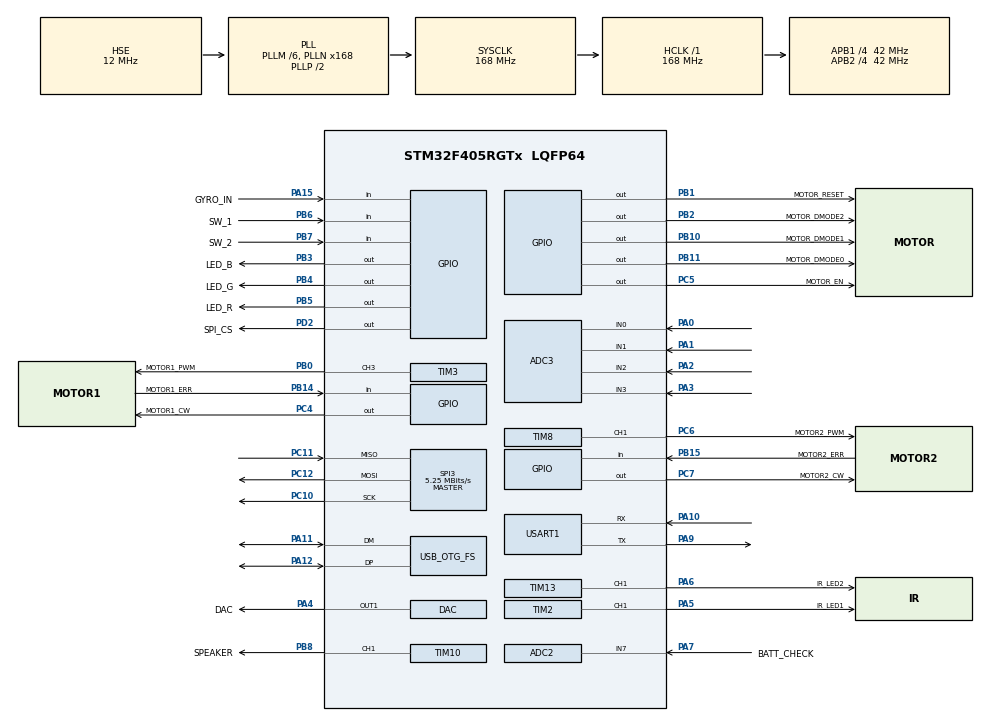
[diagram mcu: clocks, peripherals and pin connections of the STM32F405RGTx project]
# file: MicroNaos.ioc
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ADC2.Channel-0\#ChannelRegularConversion=ADC_CHANNEL_7
ADC2.ContinuousConvMode=DISABLE
ADC2.DMAContinuousRequests=DISABLE
ADC2.NbrOfConversionFlag=1
ADC2.Rank-0\#ChannelRegularConversion=1
ADC2.SamplingTime-0\#ChannelRegularConversion=ADC_SAMPLETIME_480CYCLES
ADC2.ScanConvMode=DISABLE
ADC3.Channel-0\#ChannelRegularConversion=ADC_CHANNEL_0
ADC3.Channel-1\#ChannelRegularConversion=ADC_CHANNEL_1
ADC3.Channel-2\#ChannelRegularConversion=ADC_CHANNEL_2
ADC3.Channel-3\#ChannelRegularConversion=ADC_CHANNEL_3
ADC3.ContinuousConvMode=ENABLE
ADC3.DMAContinuousRequests=ENABLE
ADC3.NbrOfConversion=4
ADC3.NbrOfConversionFlag=1
ADC3.Rank-0\#ChannelRegularConversion=1
ADC3.Rank-1\#ChannelRegularConversion=2
ADC3.Rank-2\#ChannelRegularConversion=3
ADC3.Rank-3\#ChannelRegularConversion=4
ADC3.SamplingTime-0\#ChannelRegularConversion=ADC_SAMPLETIME_28CYCLES
ADC3.SamplingTime-1\#ChannelRegularConversion=ADC_SAMPLETIME_28CYCLES
ADC3.SamplingTime-2\#ChannelRegularConversion=ADC_SAMPLETIME_28CYCLES
ADC3.SamplingTime-3\#ChannelRegularConversion=ADC_SAMPLETIME_28CYCLES
ADC3.ScanConvMode=ENABLE
Dma.ADC3.0.Direction=DMA_PERIPH_TO_MEMORY
Dma.ADC3.0.FIFOMode=DMA_FIFOMODE_DISABLE
Dma.ADC3.0.Instance=DMA2_Stream1
Dma.ADC3.0.MemDataAlignment=DMA_MDATAALIGN_HALFWORD
Dma.ADC3.0.MemInc=DMA_MINC_ENABLE
Dma.ADC3.0.Mode=DMA_CIRCULAR
Dma.ADC3.0.PeriphDataAlignment=DMA_PDATAALIGN_HALFWORD
Dma.ADC3.0.PeriphInc=DMA_PINC_DISABLE
Dma.ADC3.0.Priority=DMA_PRIORITY_VERY_HIGH
Dma.Request0=ADC3
Mcu.Family=STM32F4
Mcu.Name=STM32F405RGTx
Mcu.Package=LQFP64
NVIC.DMA2_Stream1_IRQn=true\:0\:0\:false\:false\:true\:false\:true\:true
NVIC.OTG_FS_IRQn=true\:0\:0\:false\:false\:true\:false\:true\:true
NVIC.PriorityGroup=NVIC_PRIORITYGROUP_4
NVIC.TIM1_TRG_COM_TIM11_IRQn=true\:0\:0\:false\:false\:true\:true\:true\:true
NVIC.TIM3_IRQn=true\:0\:0\:false\:false\:true\:true\:true\:true
NVIC.TIM6_DAC_IRQn=true\:0\:0\:false\:false\:true\:true\:true\:true
NVIC.TIM7_IRQn=true\:0\:0\:false\:false\:true\:true\:true\:true
NVIC.TIM8_UP_TIM13_IRQn=true\:0\:0\:false\:false\:true\:true\:true\:true
PA0-WKUP.Signal=ADCx_IN0
PA1.Signal=ADCx_IN1
PA10.Mode=Asynchronous
PA10.Signal=USART1_RX
PA11.Mode=Device_Only
PA11.Signal=USB_OTG_FS_DM
PA12.Mode=Device_Only
PA12.Signal=USB_OTG_FS_DP
PA13.Mode=Serial_Wire
PA13.Signal=SYS_JTMS-SWDIO
PA14.Mode=Serial_Wire
PA14.Signal=SYS_JTCK-SWCLK
PA15.GPIO_Label=GYRO_IN
PA15.Signal=GPIO_Input
PA2.Signal=ADCx_IN2
PA3.Signal=ADCx_IN3
PA4.GPIO_Label=DAC
PA4.Signal=COMP_DAC1_group
PA5.GPIO_Label=IR_LED1
PA5.Signal=S_TIM2_CH1_ETR
PA6.GPIO_Label=IR_LED2
PA6.Signal=S_TIM13_CH1
PA7.GPIO_Label=BATT_CHECK
PA7.Signal=ADCx_IN7
PA9.Mode=Asynchronous
PA9.Signal=USART1_TX
PB0.GPIO_Label=MOTOR1_PWM
PB0.Signal=S_TIM3_CH3
PB1.GPIO_Label=MOTOR_RESET
PB1.Signal=GPIO_Output
PB10.GPIO_Label=MOTOR_DMODE1
PB10.Signal=GPIO_Output
PB11.GPIO_Label=MOTOR_DMODE0
PB11.Signal=GPIO_Output
PB14.GPIO_Label=MOTOR1_ERR
PB14.Signal=GPIO_Input
PB15.GPIO_Label=MOTOR2_ERR
PB15.Signal=GPIO_Input
PB2.GPIO_Label=MOTOR_DMODE2
PB2.Signal=GPIO_Output
PB3.GPIO_Label=LED_B
PB3.Signal=GPIO_Output
PB4.GPIO_Label=LED_G
PB4.Signal=GPIO_Output
PB5.GPIO_Label=LED_R
PB5.Signal=GPIO_Output
PB6.GPIO_Label=SW_1
PB6.GPIO_PuPd=GPIO_PULLUP
PB6.Signal=GPIO_Input
PB7.GPIO_Label=SW_2
PB7.GPIO_PuPd=GPIO_PULLUP
PB7.Signal=GPIO_Input
PB8.GPIO_Label=SPEAKER
PB8.Signal=S_TIM10_CH1
PC10.Mode=Full_Duplex_Master
PC10.Signal=SPI3_SCK
PC11.Mode=Full_Duplex_Master
PC11.Signal=SPI3_MISO
PC12.Mode=Full_Duplex_Master
PC12.Signal=SPI3_MOSI
PC4.GPIO_Label=MOTOR1_CW
PC4.Signal=GPIO_Output
PC5.GPIO_Label=MOTOR_EN
PC5.Signal=GPIO_Output
PC6.GPIO_Label=MOTOR2_PWM
PC6.Signal=S_TIM8_CH1
PC7.GPIO_Label=MOTOR2_CW
PC7.Signal=GPIO_Output
PD2.GPIO_Label=SPI_CS
PD2.Signal=GPIO_Output
PH0-OSC_IN.Mode=HSE-External-Oscillator
PH0-OSC_IN.Signal=RCC_OSC_IN
PH1-OSC_OUT.Mode=HSE-External-Oscillator
PH1-OSC_OUT.Signal=RCC_OSC_OUT
ProjectManager.HeapSize=0x200
ProjectManager.StackSize=0x400
ProjectManager.TargetToolchain=Makefile
RCC.48MHZClocksFreq_Value=48000000
RCC.AHBFreq_Value=168000000
RCC.APB1CLKDivider=RCC_HCLK_DIV4
RCC.APB1Freq_Value=42000000
RCC.APB1TimFreq_Value=84000000
RCC.APB2CLKDivider=RCC_HCLK_DIV4
RCC.APB2Freq_Value=42000000
RCC.APB2TimFreq_Value=84000000
RCC.CortexFreq_Value=168000000
RCC.HCLKFreq_Value=168000000
RCC.HSE_VALUE=12000000
RCC.HSI_VALUE=16000000
RCC.LSE_VALUE=32768
RCC.PLLM=6
RCC.PLLN=168
RCC.PLLQ=7
RCC.SYSCLKFreq_VALUE=168000000
RCC.SYSCLKSource=RCC_SYSCLKSOURCE_PLLCLK
RCC.VCOOutputFreq_Value=336000000
SH.ADCx_IN0.0=ADC1_IN0
SH.ADCx_IN0.1=ADC3_IN0,IN0
SH.ADCx_IN1.0=ADC1_IN1
SH.ADCx_IN1.1=ADC3_IN1,IN1
SH.ADCx_IN2.0=ADC1_IN2
SH.ADCx_IN2.1=ADC3_IN2,IN2
SH.ADCx_IN3.0=ADC1_IN3
SH.ADCx_IN3.1=ADC3_IN3,IN3
SH.ADCx_IN7.0=ADC2_IN7,IN7
SH.COMP_DAC1_group.0=DAC_OUT1,DAC_OUT1
SH.S_TIM10_CH1.0=TIM10_CH1,PWM Generation1 CH1
SH.S_TIM13_CH1.0=TIM13_CH1,PWM Generation1 CH1
SH.S_TIM2_CH1_ETR.0=TIM2_CH1,PWM Generation1 CH1
SH.S_TIM3_CH3.0=TIM3_CH3,PWM Generation3 CH3
SH.S_TIM8_CH1.0=TIM8_CH1,PWM Generation1 CH1
SPI3.BaudRatePrescaler=SPI_BAUDRATEPRESCALER_8
SPI3.CLKPhase=SPI_PHASE_2EDGE
SPI3.CLKPolarity=SPI_POLARITY_HIGH
SPI3.CalculateBaudRate=5.25 MBits/s
SPI3.Direction=SPI_DIRECTION_2LINES
SPI3.Mode=SPI_MODE_MASTER
SPI3.VirtualType=VM_MASTER
TIM10.Channel=TIM_CHANNEL_1
TIM11.Period=10000 - 1
TIM11.Prescaler=84 - 1
TIM13.Channel=TIM_CHANNEL_1
TIM13.Period=100 - 1
TIM13.Prescaler=84 - 1
TIM2.Channel-PWM\ Generation1\ CH1=TIM_CHANNEL_1
TIM2.Period=100 - 1
TIM2.Prescaler=84 - 1
TIM3.AutoReloadPreload=TIM_AUTORELOAD_PRELOAD_ENABLE
TIM3.Channel-PWM\ Generation3\ CH3=TIM_CHANNEL_3
TIM3.Period=1000 - 1
TIM3.Prescaler=84 - 1
TIM6.Period=525 - 1
TIM6.Prescaler=0
TIM7.Period=1000 - 1
TIM7.Prescaler=84 - 1
TIM8.AutoReloadPreload=TIM_AUTORELOAD_PRELOAD_ENABLE
TIM8.Channel-PWM\ Generation1\ CH1=TIM_CHANNEL_1
TIM8.Period=1000 - 1
TIM8.Prescaler=84 - 1
USART1.VirtualMode=VM_ASYNC
USB_DEVICE.CLASS_NAME_FS=HID
USB_DEVICE.VirtualMode-HID_FS=Hid
USB_DEVICE.VirtualModeFS=Hid_FS
USB_OTG_FS.VirtualMode=Device_Only
VP_TIM10_VS_ClockSourceINT.Mode=Enable_Timer
VP_TIM11_VS_ClockSourceINT.Mode=Enable_Timer
VP_TIM13_VS_ClockSourceINT.Mode=Enable_Timer
VP_TIM6_VS_ClockSourceINT.Mode=Enable_Timer
VP_TIM7_VS_ClockSourceINT.Mode=Enable_Timer
VP_USB_DEVICE_VS_USB_DEVICE_HID_FS.Mode=HID_FS
board=custom

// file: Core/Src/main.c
/* USER CODE BEGIN Header */
/**
  ******************************************************************************
  * @file           : main.c
  * @brief          : Main program body
  ******************************************************************************
  * @attention
  *
  * <h2><center>&copy; Copyright (c) 2021 STMicroelectronics.
  * All rights reserved.</center></h2>
  *
  * This software component is licensed by ST under BSD 3-Clause license,
  * the "License"; You may not use this file except in compliance with the
  * License. You may obtain a copy of the License at:
  *                        opensource.org/licenses/BSD-3-Clause
  *
  ******************************************************************************
  */
/* USER CODE END Header */
#include "main.h"
#include "usb_device.h"

/* USER CODE BEGIN Includes */

#include "true_main.hpp"
#include "SEGGER_RTT.h"

/* USER CODE END Includes */

 ADC_HandleTypeDef hadc2;
ADC_HandleTypeDef hadc3;
DMA_HandleTypeDef hdma_adc3;

DAC_HandleTypeDef hdac;

SPI_HandleTypeDef hspi3;

TIM_HandleTypeDef htim2;
TIM_HandleTypeDef htim3;
TIM_HandleTypeDef htim6;
TIM_HandleTypeDef htim7;
TIM_HandleTypeDef htim8;
TIM_HandleTypeDef htim10;
TIM_HandleTypeDef htim11;
TIM_HandleTypeDef htim13;

UART_HandleTypeDef huart1;

void SystemClock_Config(void);
static void MX_GPIO_Init(void);
static void MX_DAC_Init(void);
static void MX_SPI3_Init(void);
static void MX_TIM2_Init(void);
static void MX_TIM10_Init(void);
static void MX_TIM13_Init(void);
static void MX_USART1_UART_Init(void);
static void MX_DMA_Init(void);
static void MX_TIM8_Init(void);
static void MX_TIM3_Init(void);
static void MX_ADC2_Init(void);
static void MX_TIM6_Init(void);
static void MX_TIM7_Init(void);
static void MX_ADC3_Init(void);
static void MX_TIM11_Init(void);

int main(void)
{

  /* MCU Configuration--------------------------------------------------------*/

  /* Reset of all peripherals, Initializes the Flash interface and the Systick. */
  HAL_Init();

  /* Configure the system clock */
  SystemClock_Config();

  /* Initialize all configured peripherals */
  MX_GPIO_Init();
  MX_DAC_Init();
  MX_SPI3_Init();
  MX_TIM2_Init();
  MX_TIM10_Init();
  MX_TIM13_Init();
  MX_USART1_UART_Init();
  MX_USB_DEVICE_Init();
  MX_DMA_Init();
  MX_TIM8_Init();
  MX_TIM3_Init();
  MX_ADC2_Init();
  MX_TIM6_Init();
  MX_TIM7_Init();
  MX_ADC3_Init();
  MX_TIM11_Init();

  /* Infinite loop */
  /* USER CODE BEGIN WHILE */
  while (1)
  {
	  true_main();
    /* USER CODE END WHILE */

  }
}

void SystemClock_Config(void)
{
  RCC_OscInitTypeDef RCC_OscInitStruct = {0};
  RCC_ClkInitTypeDef RCC_ClkInitStruct = {0};

  /** Configure the main internal regulator output voltage
  */
  __HAL_RCC_PWR_CLK_ENABLE();
  __HAL_PWR_VOLTAGESCALING_CONFIG(PWR_REGULATOR_VOLTAGE_SCALE1);

  /** Initializes the RCC Oscillators according to the specified parameters
  * in the RCC_OscInitTypeDef structure.
  */
  RCC_OscInitStruct.OscillatorType = RCC_OSCILLATORTYPE_HSE;
  RCC_OscInitStruct.HSEState = RCC_HSE_ON;
  RCC_OscInitStruct.PLL.PLLState = RCC_PLL_ON;
  RCC_OscInitStruct.PLL.PLLSource = RCC_PLLSOURCE_HSE;
  RCC_OscInitStruct.PLL.PLLM = 6;
  RCC_OscInitStruct.PLL.PLLN = 168;
  RCC_OscInitStruct.PLL.PLLP = RCC_PLLP_DIV2;
  RCC_OscInitStruct.PLL.PLLQ = 7;
  if (HAL_RCC_OscConfig(&RCC_OscInitStruct) != HAL_OK)
  {
    Error_Handler();
  }

  /** Initializes the CPU, AHB and APB buses clocks
  */
  RCC_ClkInitStruct.ClockType = RCC_CLOCKTYPE_HCLK|RCC_CLOCKTYPE_SYSCLK
                              |RCC_CLOCKTYPE_PCLK1|RCC_CLOCKTYPE_PCLK2;
  RCC_ClkInitStruct.SYSCLKSource = RCC_SYSCLKSOURCE_PLLCLK;
  RCC_ClkInitStruct.AHBCLKDivider = RCC_SYSCLK_DIV1;
  RCC_ClkInitStruct.APB1CLKDivider = RCC_HCLK_DIV4;
  RCC_ClkInitStruct.APB2CLKDivider = RCC_HCLK_DIV4;

  if (HAL_RCC_ClockConfig(&RCC_ClkInitStruct, FLASH_LATENCY_5) != HAL_OK)
  {
    Error_Handler();
  }
}

static void MX_ADC2_Init(void)
{

  ADC_ChannelConfTypeDef sConfig = {0};

  /** Configure the global features of the ADC (Clock, Resolution, Data Alignment and number of conversion)
  */
  hadc2.Instance = ADC2;
  hadc2.Init.ClockPrescaler = ADC_CLOCK_SYNC_PCLK_DIV2;
  hadc2.Init.Resolution = ADC_RESOLUTION_12B;
  hadc2.Init.ScanConvMode = DISABLE;
  hadc2.Init.ContinuousConvMode = DISABLE;
  hadc2.Init.DiscontinuousConvMode = DISABLE;
  hadc2.Init.ExternalTrigConvEdge = ADC_EXTERNALTRIGCONVEDGE_NONE;
  hadc2.Init.ExternalTrigConv = ADC_SOFTWARE_START;
  hadc2.Init.DataAlign = ADC_DATAALIGN_RIGHT;
  hadc2.Init.NbrOfConversion = 1;
  hadc2.Init.DMAContinuousRequests = DISABLE;
  hadc2.Init.EOCSelection = ADC_EOC_SINGLE_CONV;
  if (HAL_ADC_Init(&hadc2) != HAL_OK)
  {
    Error_Handler();
  }

  /** Configure for the selected ADC regular channel its corresponding rank in the sequencer and its sample time.
  */
  sConfig.Channel = ADC_CHANNEL_7;
  sConfig.Rank = 1;
  sConfig.SamplingTime = ADC_SAMPLETIME_480CYCLES;
  if (HAL_ADC_ConfigChannel(&hadc2, &sConfig) != HAL_OK)
  {
    Error_Handler();
  }

}

static void MX_ADC3_Init(void)
{

  ADC_ChannelConfTypeDef sConfig = {0};

  /** Configure the global features of the ADC (Clock, Resolution, Data Alignment and number of conversion)
  */
  hadc3.Instance = ADC3;
  hadc3.Init.ClockPrescaler = ADC_CLOCK_SYNC_PCLK_DIV2;
  hadc3.Init.Resolution = ADC_RESOLUTION_12B;
  hadc3.Init.ScanConvMode = ENABLE;
  hadc3.Init.ContinuousConvMode = ENABLE;
  hadc3.Init.DiscontinuousConvMode = DISABLE;
  hadc3.Init.ExternalTrigConvEdge = ADC_EXTERNALTRIGCONVEDGE_NONE;
  hadc3.Init.ExternalTrigConv = ADC_SOFTWARE_START;
  hadc3.Init.DataAlign = ADC_DATAALIGN_RIGHT;
  hadc3.Init.NbrOfConversion = 4;
  hadc3.Init.DMAContinuousRequests = ENABLE;
  hadc3.Init.EOCSelection = ADC_EOC_SINGLE_CONV;
  if (HAL_ADC_Init(&hadc3) != HAL_OK)
  {
    Error_Handler();
  }

  /** Configure for the selected ADC regular channel its corresponding rank in the sequencer and its sample time.
  */
  sConfig.Channel = ADC_CHANNEL_0;
  sConfig.Rank = 1;
  sConfig.SamplingTime = ADC_SAMPLETIME_28CYCLES;
  if (HAL_ADC_ConfigChannel(&hadc3, &sConfig) != HAL_OK)
  {
    Error_Handler();
  }

  /** Configure for the selected ADC regular channel its corresponding rank in the sequencer and its sample time.
  */
  sConfig.Channel = ADC_CHANNEL_1;
  sConfig.Rank = 2;
  if (HAL_ADC_ConfigChannel(&hadc3, &sConfig) != HAL_OK)
  {
    Error_Handler();
  }

  /** Configure for the selected ADC regular channel its corresponding rank in the sequencer and its sample time.
  */
  sConfig.Channel = ADC_CHANNEL_2;
  sConfig.Rank = 3;
  if (HAL_ADC_ConfigChannel(&hadc3, &sConfig) != HAL_OK)
  {
    Error_Handler();
  }

  /** Configure for the selected ADC regular channel its corresponding rank in the sequencer and its sample time.
  */
  sConfig.Channel = ADC_CHANNEL_3;
  sConfig.Rank = 4;
  if (HAL_ADC_ConfigChannel(&hadc3, &sConfig) != HAL_OK)
  {
    Error_Handler();
  }

}

static void MX_DAC_Init(void)
{

  DAC_ChannelConfTypeDef sConfig = {0};

  /** DAC Initialization
  */
  hdac.Instance = DAC;
  if (HAL_DAC_Init(&hdac) != HAL_OK)
  {
    Error_Handler();
  }

  /** DAC channel OUT1 config
  */
  sConfig.DAC_Trigger = DAC_TRIGGER_NONE;
  sConfig.DAC_OutputBuffer = DAC_OUTPUTBUFFER_ENABLE;
  if (HAL_DAC_ConfigChannel(&hdac, &sConfig, DAC_CHANNEL_1) != HAL_OK)
  {
    Error_Handler();
  }

}

static void MX_SPI3_Init(void)
{

  /* SPI3 parameter configuration*/
  hspi3.Instance = SPI3;
  hspi3.Init.Mode = SPI_MODE_MASTER;
  hspi3.Init.Direction = SPI_DIRECTION_2LINES;
  hspi3.Init.DataSize = SPI_DATASIZE_8BIT;
  hspi3.Init.CLKPolarity = SPI_POLARITY_HIGH;
  hspi3.Init.CLKPhase = SPI_PHASE_2EDGE;
  hspi3.Init.NSS = SPI_NSS_SOFT;
  hspi3.Init.BaudRatePrescaler = SPI_BAUDRATEPRESCALER_8;
  hspi3.Init.FirstBit = SPI_FIRSTBIT_MSB;
  hspi3.Init.TIMode = SPI_TIMODE_DISABLE;
  hspi3.Init.CRCCalculation = SPI_CRCCALCULATION_DISABLE;
  hspi3.Init.CRCPolynomial = 10;
  if (HAL_SPI_Init(&hspi3) != HAL_OK)
  {
    Error_Handler();
  }

}

static void MX_TIM2_Init(void)
{

  TIM_MasterConfigTypeDef sMasterConfig = {0};
  TIM_OC_InitTypeDef sConfigOC = {0};

  htim2.Instance = TIM2;
  htim2.Init.Prescaler = 84 - 1;
  htim2.Init.CounterMode = TIM_COUNTERMODE_UP;
  htim2.Init.Period = 100 - 1;
  htim2.Init.ClockDivision = TIM_CLOCKDIVISION_DIV1;
  htim2.Init.AutoReloadPreload = TIM_AUTORELOAD_PRELOAD_DISABLE;
  if (HAL_TIM_PWM_Init(&htim2) != HAL_OK)
  {
    Error_Handler();
  }
  sMasterConfig.MasterOutputTrigger = TIM_TRGO_RESET;
  sMasterConfig.MasterSlaveMode = TIM_MASTERSLAVEMODE_DISABLE;
  if (HAL_TIMEx_MasterConfigSynchronization(&htim2, &sMasterConfig) != HAL_OK)
  {
    Error_Handler();
  }
  sConfigOC.OCMode = TIM_OCMODE_PWM1;
  sConfigOC.Pulse = 0;
  sConfigOC.OCPolarity = TIM_OCPOLARITY_HIGH;
  sConfigOC.OCFastMode = TIM_OCFAST_DISABLE;
  if (HAL_TIM_PWM_ConfigChannel(&htim2, &sConfigOC, TIM_CHANNEL_1) != HAL_OK)
  {
    Error_Handler();
  }
  HAL_TIM_MspPostInit(&htim2);

}

static void MX_TIM3_Init(void)
{

  TIM_MasterConfigTypeDef sMasterConfig = {0};
  TIM_OC_InitTypeDef sConfigOC = {0};

  htim3.Instance = TIM3;
  htim3.Init.Prescaler = 84 - 1;
  htim3.Init.CounterMode = TIM_COUNTERMODE_UP;
  htim3.Init.Period = 1000 - 1;
  htim3.Init.ClockDivision = TIM_CLOCKDIVISION_DIV1;
  htim3.Init.AutoReloadPreload = TIM_AUTORELOAD_PRELOAD_ENABLE;
  if (HAL_TIM_PWM_Init(&htim3) != HAL_OK)
  {
    Error_Handler();
  }
  sMasterConfig.MasterOutputTrigger = TIM_TRGO_RESET;
  sMasterConfig.MasterSlaveMode = TIM_MASTERSLAVEMODE_DISABLE;
  if (HAL_TIMEx_MasterConfigSynchronization(&htim3, &sMasterConfig) != HAL_OK)
  {
    Error_Handler();
  }
  sConfigOC.OCMode = TIM_OCMODE_PWM1;
  sConfigOC.Pulse = 0;
  sConfigOC.OCPolarity = TIM_OCPOLARITY_HIGH;
  sConfigOC.OCFastMode = TIM_OCFAST_DISABLE;
  if (HAL_TIM_PWM_ConfigChannel(&htim3, &sConfigOC, TIM_CHANNEL_3) != HAL_OK)
  {
    Error_Handler();
  }
  HAL_TIM_MspPostInit(&htim3);

}

static void MX_TIM6_Init(void)
{

  TIM_MasterConfigTypeDef sMasterConfig = {0};

  htim6.Instance = TIM6;
  htim6.Init.Prescaler = 0;
  htim6.Init.CounterMode = TIM_COUNTERMODE_UP;
  htim6.Init.Period = 525 - 1;
  htim6.Init.AutoReloadPreload = TIM_AUTORELOAD_PRELOAD_DISABLE;
  if (HAL_TIM_Base_Init(&htim6) != HAL_OK)
  {
    Error_Handler();
  }
  sMasterConfig.MasterOutputTrigger = TIM_TRGO_RESET;
  sMasterConfig.MasterSlaveMode = TIM_MASTERSLAVEMODE_DISABLE;
  if (HAL_TIMEx_MasterConfigSynchronization(&htim6, &sMasterConfig) != HAL_OK)
  {
    Error_Handler();
  }

}

static void MX_TIM7_Init(void)
{

  TIM_MasterConfigTypeDef sMasterConfig = {0};

  htim7.Instance = TIM7;
  htim7.Init.Prescaler = 84 - 1;
  htim7.Init.CounterMode = TIM_COUNTERMODE_UP;
  htim7.Init.Period = 1000 - 1;
  htim7.Init.AutoReloadPreload = TIM_AUTORELOAD_PRELOAD_DISABLE;
  if (HAL_TIM_Base_Init(&htim7) != HAL_OK)
  {
    Error_Handler();
  }
  sMasterConfig.MasterOutputTrigger = TIM_TRGO_RESET;
  sMasterConfig.MasterSlaveMode = TIM_MASTERSLAVEMODE_DISABLE;
  if (HAL_TIMEx_MasterConfigSynchronization(&htim7, &sMasterConfig) != HAL_OK)
  {
    Error_Handler();
  }

}

static void MX_TIM8_Init(void)
{

  TIM_MasterConfigTypeDef sMasterConfig = {0};
  TIM_OC_InitTypeDef sConfigOC = {0};
  TIM_BreakDeadTimeConfigTypeDef sBreakDeadTimeConfig = {0};

  htim8.Instance = TIM8;
  htim8.Init.Prescaler = 84 - 1;
  htim8.Init.CounterMode = TIM_COUNTERMODE_UP;
  htim8.Init.Period = 1000 - 1;
  htim8.Init.ClockDivision = TIM_CLOCKDIVISION_DIV1;
  htim8.Init.RepetitionCounter = 0;
  htim8.Init.AutoReloadPreload = TIM_AUTORELOAD_PRELOAD_ENABLE;
  if (HAL_TIM_PWM_Init(&htim8) != HAL_OK)
  {
    Error_Handler();
  }
  sMasterConfig.MasterOutputTrigger = TIM_TRGO_RESET;
  sMasterConfig.MasterSlaveMode = TIM_MASTERSLAVEMODE_DISABLE;
  if (HAL_TIMEx_MasterConfigSynchronization(&htim8, &sMasterConfig) != HAL_OK)
  {
    Error_Handler();
  }
  sConfigOC.OCMode = TIM_OCMODE_PWM1;
  sConfigOC.Pulse = 0;
  sConfigOC.OCPolarity = TIM_OCPOLARITY_HIGH;
  sConfigOC.OCNPolarity = TIM_OCNPOLARITY_HIGH;
  sConfigOC.OCFastMode = TIM_OCFAST_DISABLE;
  sConfigOC.OCIdleState = TIM_OCIDLESTATE_RESET;
  sConfigOC.OCNIdleState = TIM_OCNIDLESTATE_RESET;
  if (HAL_TIM_PWM_ConfigChannel(&htim8, &sConfigOC, TIM_CHANNEL_1) != HAL_OK)
  {
    Error_Handler();
  }
  sBreakDeadTimeConfig.OffStateRunMode = TIM_OSSR_DISABLE;
  sBreakDeadTimeConfig.OffStateIDLEMode = TIM_OSSI_DISABLE;
  sBreakDeadTimeConfig.LockLevel = TIM_LOCKLEVEL_OFF;
  sBreakDeadTimeConfig.DeadTime = 0;
  sBreakDeadTimeConfig.BreakState = TIM_BREAK_DISABLE;
  sBreakDeadTimeConfig.BreakPolarity = TIM_BREAKPOLARITY_HIGH;
  sBreakDeadTimeConfig.AutomaticOutput = TIM_AUTOMATICOUTPUT_DISABLE;
  if (HAL_TIMEx_ConfigBreakDeadTime(&htim8, &sBreakDeadTimeConfig) != HAL_OK)
  {
    Error_Handler();
  }
  HAL_TIM_MspPostInit(&htim8);

}

static void MX_TIM10_Init(void)
{

  TIM_OC_InitTypeDef sConfigOC = {0};

  htim10.Instance = TIM10;
  htim10.Init.Prescaler = 0;
  htim10.Init.CounterMode = TIM_COUNTERMODE_UP;
  htim10.Init.Period = 65535;
  htim10.Init.ClockDivision = TIM_CLOCKDIVISION_DIV1;
  htim10.Init.AutoReloadPreload = TIM_AUTORELOAD_PRELOAD_DISABLE;
  if (HAL_TIM_Base_Init(&htim10) != HAL_OK)
  {
    Error_Handler();
  }
  if (HAL_TIM_PWM_Init(&htim10) != HAL_OK)
  {
    Error_Handler();
  }
  sConfigOC.OCMode = TIM_OCMODE_PWM1;
  sConfigOC.Pulse = 0;
  sConfigOC.OCPolarity = TIM_OCPOLARITY_HIGH;
  sConfigOC.OCFastMode = TIM_OCFAST_DISABLE;
  if (HAL_TIM_PWM_ConfigChannel(&htim10, &sConfigOC, TIM_CHANNEL_1) != HAL_OK)
  {
    Error_Handler();
  }
  HAL_TIM_MspPostInit(&htim10);

}

static void MX_TIM11_Init(void)
{

  htim11.Instance = TIM11;
  htim11.Init.Prescaler = 84 - 1;
  htim11.Init.CounterMode = TIM_COUNTERMODE_UP;
  htim11.Init.Period = 10000 - 1;
  htim11.Init.ClockDivision = TIM_CLOCKDIVISION_DIV1;
  htim11.Init.AutoReloadPreload = TIM_AUTORELOAD_PRELOAD_DISABLE;
  if (HAL_TIM_Base_Init(&htim11) != HAL_OK)
  {
    Error_Handler();
  }

}

static void MX_TIM13_Init(void)
{

  TIM_OC_InitTypeDef sConfigOC = {0};

  htim13.Instance = TIM13;
  htim13.Init.Prescaler = 84 - 1;
  htim13.Init.CounterMode = TIM_COUNTERMODE_UP;
  htim13.Init.Period = 100 - 1;
  htim13.Init.ClockDivision = TIM_CLOCKDIVISION_DIV1;
  htim13.Init.AutoReloadPreload = TIM_AUTORELOAD_PRELOAD_DISABLE;
  if (HAL_TIM_Base_Init(&htim13) != HAL_OK)
  {
    Error_Handler();
  }
  if (HAL_TIM_PWM_Init(&htim13) != HAL_OK)
  {
    Error_Handler();
  }
  sConfigOC.OCMode = TIM_OCMODE_PWM1;
  sConfigOC.Pulse = 0;
  sConfigOC.OCPolarity = TIM_OCPOLARITY_HIGH;
  sConfigOC.OCFastMode = TIM_OCFAST_DISABLE;
  if (HAL_TIM_PWM_ConfigChannel(&htim13, &sConfigOC, TIM_CHANNEL_1) != HAL_OK)
  {
    Error_Handler();
  }
  HAL_TIM_MspPostInit(&htim13);

}

static void MX_USART1_UART_Init(void)
{

  huart1.Instance = USART1;
  huart1.Init.BaudRate = 115200;
  huart1.Init.WordLength = UART_WORDLENGTH_8B;
  huart1.Init.StopBits = UART_STOPBITS_1;
  huart1.Init.Parity = UART_PARITY_NONE;
  huart1.Init.Mode = UART_MODE_TX_RX;
  huart1.Init.HwFlowCtl = UART_HWCONTROL_NONE;
  huart1.Init.OverSampling = UART_OVERSAMPLING_16;
  if (HAL_UART_Init(&huart1) != HAL_OK)
  {
    Error_Handler();
  }

}

static void MX_DMA_Init(void)
{

  /* DMA controller clock enable */
  __HAL_RCC_DMA2_CLK_ENABLE();

  /* DMA interrupt init */
  /* DMA2_Stream1_IRQn interrupt configuration */
  HAL_NVIC_SetPriority(DMA2_Stream1_IRQn, 0, 0);
  HAL_NVIC_EnableIRQ(DMA2_Stream1_IRQn);

}

static void MX_GPIO_Init(void)
{
  GPIO_InitTypeDef GPIO_InitStruct = {0};

  /* GPIO Ports Clock Enable */
  __HAL_RCC_GPIOH_CLK_ENABLE();
  __HAL_RCC_GPIOA_CLK_ENABLE();
  __HAL_RCC_GPIOC_CLK_ENABLE();
  __HAL_RCC_GPIOB_CLK_ENABLE();
  __HAL_RCC_GPIOD_CLK_ENABLE();

  /*Configure GPIO pin Output Level */
  HAL_GPIO_WritePin(GPIOC, MOTOR1_CW_Pin|MOTOR_EN_Pin|MOTOR2_CW_Pin, GPIO_PIN_RESET);

  /*Configure GPIO pin Output Level */
  HAL_GPIO_WritePin(GPIOB, MOTOR_RESET_Pin|MOTOR_DMODE2_Pin|MOTOR_DMODE1_Pin|MOTOR_DMODE0_Pin
                          |LED_B_Pin|LED_G_Pin|LED_R_Pin, GPIO_PIN_RESET);

  /*Configure GPIO pin Output Level */
  HAL_GPIO_WritePin(SPI_CS_GPIO_Port, SPI_CS_Pin, GPIO_PIN_RESET);

  /*Configure GPIO pins : PA0 PA1 PA2 PA3 */
  GPIO_InitStruct.Pin = GPIO_PIN_0|GPIO_PIN_1|GPIO_PIN_2|GPIO_PIN_3;
  GPIO_InitStruct.Mode = GPIO_MODE_ANALOG;
  GPIO_InitStruct.Pull = GPIO_NOPULL;
  HAL_GPIO_Init(GPIOA, &GPIO_InitStruct);

  /*Configure GPIO pins : MOTOR1_CW_Pin MOTOR_EN_Pin MOTOR2_CW_Pin */
  GPIO_InitStruct.Pin = MOTOR1_CW_Pin|MOTOR_EN_Pin|MOTOR2_CW_Pin;
  GPIO_InitStruct.Mode = GPIO_MODE_OUTPUT_PP;
  GPIO_InitStruct.Pull = GPIO_NOPULL;
  GPIO_InitStruct.Speed = GPIO_SPEED_FREQ_LOW;
  HAL_GPIO_Init(GPIOC, &GPIO_InitStruct);

  /*Configure GPIO pins : MOTOR_RESET_Pin MOTOR_DMODE2_Pin MOTOR_DMODE1_Pin MOTOR_DMODE0_Pin
                           LED_B_Pin LED_G_Pin LED_R_Pin */
  GPIO_InitStruct.Pin = MOTOR_RESET_Pin|MOTOR_DMODE2_Pin|MOTOR_DMODE1_Pin|MOTOR_DMODE0_Pin
                          |LED_B_Pin|LED_G_Pin|LED_R_Pin;
  GPIO_InitStruct.Mode = GPIO_MODE_OUTPUT_PP;
  GPIO_InitStruct.Pull = GPIO_NOPULL;
  GPIO_InitStruct.Speed = GPIO_SPEED_FREQ_LOW;
  HAL_GPIO_Init(GPIOB, &GPIO_InitStruct);

  /*Configure GPIO pins : MOTOR1_ERR_Pin MOTOR2_ERR_Pin */
  GPIO_InitStruct.Pin = MOTOR1_ERR_Pin|MOTOR2_ERR_Pin;
  GPIO_InitStruct.Mode = GPIO_MODE_INPUT;
  GPIO_InitStruct.Pull = GPIO_NOPULL;
  HAL_GPIO_Init(GPIOB, &GPIO_InitStruct);

  /*Configure GPIO pin : GYRO_IN_Pin */
  GPIO_InitStruct.Pin = GYRO_IN_Pin;
  GPIO_InitStruct.Mode = GPIO_MODE_INPUT;
  GPIO_InitStruct.Pull = GPIO_NOPULL;
  HAL_GPIO_Init(GYRO_IN_GPIO_Port, &GPIO_InitStruct);

  /*Configure GPIO pin : SPI_CS_Pin */
  GPIO_InitStruct.Pin = SPI_CS_Pin;
  GPIO_InitStruct.Mode = GPIO_MODE_OUTPUT_PP;
  GPIO_InitStruct.Pull = GPIO_NOPULL;
  GPIO_InitStruct.Speed = GPIO_SPEED_FREQ_LOW;
  HAL_GPIO_Init(SPI_CS_GPIO_Port, &GPIO_InitStruct);

  /*Configure GPIO pins : SW_1_Pin SW_2_Pin */
  GPIO_InitStruct.Pin = SW_1_Pin|SW_2_Pin;
  GPIO_InitStruct.Mode = GPIO_MODE_INPUT;
  GPIO_InitStruct.Pull = GPIO_PULLUP;
  HAL_GPIO_Init(GPIOB, &GPIO_InitStruct);

}

void Error_Handler(void)
{
  /* USER CODE BEGIN Error_Handler_Debug */
  /* User can add his own implementation to report the HAL error return state */
  __disable_irq();
  while (1)
  {
	  SEGGER_RTT_printf(0, "Error!!!");
	  HAL_Delay(500);
  }
  /* USER CODE END Error_Handler_Debug */
}
